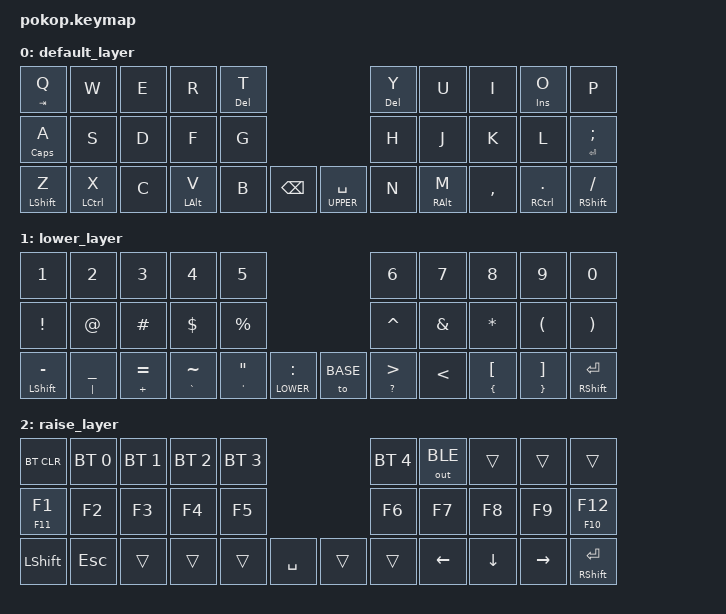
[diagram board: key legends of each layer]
/*
 * Copyright (c) 2020 The ZMK Contributors
 *
 * SPDX-License-Identifier: MIT
 */

#include <behaviors.dtsi>
#include <dt-bindings/zmk/keys.h>
#include <dt-bindings/zmk/bt.h>
#include <dt-bindings/zmk/ext_power.h>
#include <dt-bindings/zmk/outputs.h>

#define BASE 0
#define UPPER 1
#define LOWER 2

//#define MO_TOG(layer) &mo_tog layer layer

    &mt {
        tapping-term-ms = <500>;
    };

/ {
    behaviors {
        mo_tog: behavior_mo_tog {
            compatible = "zmk,behavior-hold-tap";
            #binding-cells = <2>;
            flavor = "hold-preferred";
            tapping-term-ms = <500>;
            bindings = <&mo>, <&kp>;
        };
    };
     
     keymap {
        compatible = "zmk,keymap";
        default_layer {
// -------------------------------------------------                             -------------------------------------------------
// | Key: Q    | Key: W | Key: E | Key: R | Key: T |                             | Key: Y | Key: U | Key: I | Key: O | Key: P    |
// | Pos: 1    | Pos: 2 | Pos: 3 | Pos: 4 | Pos: 5 |                             | Pos: 6 | Pos: 7 | Pos: 8 | Pos: 9 | Pos: 10   |
// | 2nd: TAB  |                          | 2nd:DEL|                             | 2nd:DEL|                 | 2nd:INS| 2nd: BACK |
// -------------------------------------------------                             -------------------------------------------------
// | Key: A    | Key: S | Key: D | Key: F | Key: G |                             | Key: H | Key: J | Key: K | Key: L | Key: ;    |
// | Pos: 11   | Pos: 12| Pos: 13| Pos: 14| Pos: 15|                             | Pos: 16| Pos: 17| Pos: 18| Pos: 19| Pos: 20   |
// | 2nd: CAPS |                                                                                                     | 2nd: ENTER|
// -------------------------------------------------------------------------------------------------------------------------------
// | Key: Z    | Key: X | Key: C | Key: V | Key: B | Key: SPACE |   | Key: LOWER | Key: N | Key: M | Key: , | Key; . | Key: /    |
// | Pos: 21   | Pos: 22| Pos: 23| Pos: 24| Pos: 25| Pos: 26    |   | Pos:  27   | Pos: 28| Pos: 29| Pos: 30| Pos: 31| Pos: 32   |
// | 2nd: Shift| 2nd:CRT|--------| 2nd:ALT|--------| 2nd: ESCAPE|   | 2nd: UPPER |--------| 2nd:ALT|--------|2nd: CRT| 2nd: Shift|
// ----------------------        ----------        --------------   --------------        ----------        ----------------------
            bindings = < 
&mt TAB Q    &kp W        &kp E  &kp R      &mt DEL T                           &mt DEL Y  &kp U        &kp I          &mt INS O   &kp P
&mt CAPS A   &kp S        &kp D  &kp F      &kp G                               &kp H      &kp J        &kp K          &kp L       &mt ENTER SEMI
&mt LSHFT Z  &mt LCTRL X  &kp C  &mt LALT V &kp B  &kp BACKSPACE  &mo_tog UPPER SPACE &kp N      &mt RALT M  &kp COMMA &mt RCTRL DOT &mt RSHFT FSLH
            >;
            sensor-bindings = <&inc_dec_kp C_VOL_UP C_VOL_DN>;
        };
        lower_layer {
// -------------------------------------------------                             -------------------------------------------------
// | Key: 1    | Key: 2 | Key: 3 | Key: 4 | Key: 5 |                             | Key: 6 | Key: 7 | Key: 8 | Key: 9 | Key: 10   |
// | Pos: 1    | Pos: 2 | Pos: 3 | Pos: 4 | Pos: 5 |                             | Pos: 6 | Pos: 7 | Pos: 8 | Pos: 9 | Pos: 10   |
// -------------------------------------------------                             -------------------------------------------------
// | Key: !    | Key: @ | Key: # | Key: $ | Key: % |                             | Key: ^ | Key: & | Key: * | Key: ( | Key: )    |
// | Pos: 11   | Pos: 12| Pos: 13| Pos: 14| Pos: 15|                             | Pos: 16| Pos: 17| Pos: 18| Pos: 19| Pos: 20   |
// -------------------------------------------------------------------------------------------------------------------------------
// | Key: -    | Key: _ | Key: = | Key: ~ | Key: " | Key: :     |   | Key: Base  | Key: > | Key: < | Key: [ | Key: ] | Key: ENTER|
// | Pos: 21   | Pos: 22| Pos: 23| Pos: 24| Pos: 25| Pos: 26    |   | Pos:  27   | Pos: 28| Pos: 29| Pos: 30| Pos: 31| Pos: 32   |
// | 2nd: Shift| 2nd: | | 2nd: + | 2nd: ` | 2nd: ' | 2nd: LOWER |   | 2nd: UPPER | 2nd: ? | 2nd:   | 2nd: { | 2nd: } | 2nd: Shift|
// -------------------------------------------------------------------------------------------------------------------------------
            bindings = <
&kp N1 &kp N2 &kp N3 &kp N4 &kp N5       &kp N6 &kp N7 &kp N8 &kp N9 &kp N0
&kp EXCL &kp AT &kp HASH &kp DOLLAR &kp PERCENT       &kp CARET &kp AMPS &kp STAR &kp LPAR &kp RPAR
&mt LSHFT MINUS &mt PIPE UNDER &mt PLUS EQUAL &mt GRAVE TILDE &mt APOS DQT &mo_tog LOWER COLON    &to BASE &mt QMARK GT &kp LT &mt LBRC LBKT &mt RBRC RBKT&mt RSHFT ENTER
            >;
            sensor-bindings = <&inc_dec_kp C_VOL_UP C_VOL_DN>;
        };
        raise_layer {
// -------------------------------------------------                             -------------------------------------------------
// | Key: BTCLR| Key:BT1| Key:BT2| Key:BT3| Key:BT4|                             | Key:BT5| Key:   | Key:   | Key:   | Key:      |
// | Pos: 1    | Pos: 2 | Pos: 3 | Pos: 4 | Pos: 5 |                             | Pos: 6 | Pos: 7 | Pos: 8 | Pos: 9 | Pos: 10   |
// | 2nd:      |------------------------------------                             ------------------------------------| 2nd:      |
// -------------                                                                                                     -------------
// | Key:      | Key:   | Key:   | Key:   | Key:   |                             | Key:   | Key:   | Key: UP| Key:   | Key:      |
// | Pos: 11   | Pos: 12| Pos: 13| Pos: 14| Pos: 15|                             | Pos: 16| Pos: 17| Pos: 18| Pos: 19| Pos: 20   |
// | 2nd:      | 2nd:   | 2nd:   | 2nd:   | 2nd:   |                             | 2nd:   | 2nd:   | 2nd:   | 2nd:   | 2nd:      |
// -------------------------------------------------------------------------------------------------------------------------------
// | Key: SHIFT| Key:   | Key:   | Key:   | Key:   | Key: SPACE |   | Key: BASE  | Key:   | Key: LEFT | Key: DOWN | Key: RIGHT | Key: ENTER|
// | Pos: 21   | Pos: 22| Pos: 23| Pos: 24| Pos: 25| Pos: 26    |   | Pos:  27   | Pos: 28| Pos: 29   | Pos: 30   | Pos: 31    | Pos: 32   |
// | 2nd:      | 2nd:   | 2nd:   | 2nd:   | 2nd:   | 2nd:       |   | 2nd: LOWER | 2nd:   | 2nd:      | 2nd:      | 2nd:       | 2nd: Shift|
// -------------------------------------------------------------------------------------------------------------------------------
            bindings = <
  &bt BT_CLR &bt BT_SEL 0 &bt BT_SEL 1 &bt BT_SEL 2 &bt BT_SEL 3                               &bt BT_SEL 4 &out OUT_BLE  &trans   &trans    &trans
  &mt F11 F1 &kp F2 &kp F3 &kp F4 &kp F5       &kp F6 &kp F7 &kp F8 &kp F9 &mt F10 F12
  &kp LSHFT &kp ESC     &trans       &trans       &trans  &kp SPACE              &trans   &trans       &kp LEFT &kp DOWN &kp RIGHT &mt RSHFT ENTER
            >;
            sensor-bindings = <&inc_dec_kp C_VOL_UP C_VOL_DN>;
        };
    };
};
